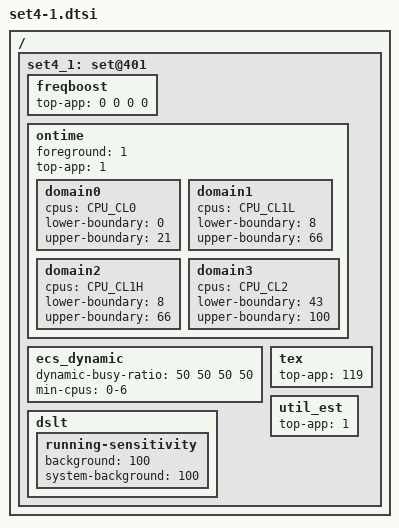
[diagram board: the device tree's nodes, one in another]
/ {
	/* balance mode - touch boost */
	set4_1: set@401{
		/* Boosting margin applied to frequency selection */
		freqboost {	   		/* LIT MED-L MED-H BIG */
			top-app         	= <  0  0  0  0 >;
		};

		/* Ontime Migration */
		ontime {
			foreground 	= <1>;
			top-app		= <1>;

			domain0 {
				cpus = CPU_CL0;
				lower-boundary = <0>;
				upper-boundary = <21>;
			};
			domain1 {
				cpus = CPU_CL1L;
				lower-boundary = <8>;
				upper-boundary = <66>;
			};
			domain2 {
				cpus = CPU_CL1H;
				lower-boundary = <8>;
				upper-boundary = <66>;
			};
			domain3 {
				cpus = CPU_CL2;
				lower-boundary = <43>;
				upper-boundary = <100>;
			};
		};

		ecs_dynamic {
			dynamic-busy-ratio = <50 50 50 50>;
			min-cpus = "0-6";
		};

		tex {
			top-app = <119>;
		};

		util_est {
			top-app	= <1>;
		};

		dslt {
			running-sensitivity {
				background = <100>;
				system-background = <100>;
			};
		};
	};
};
